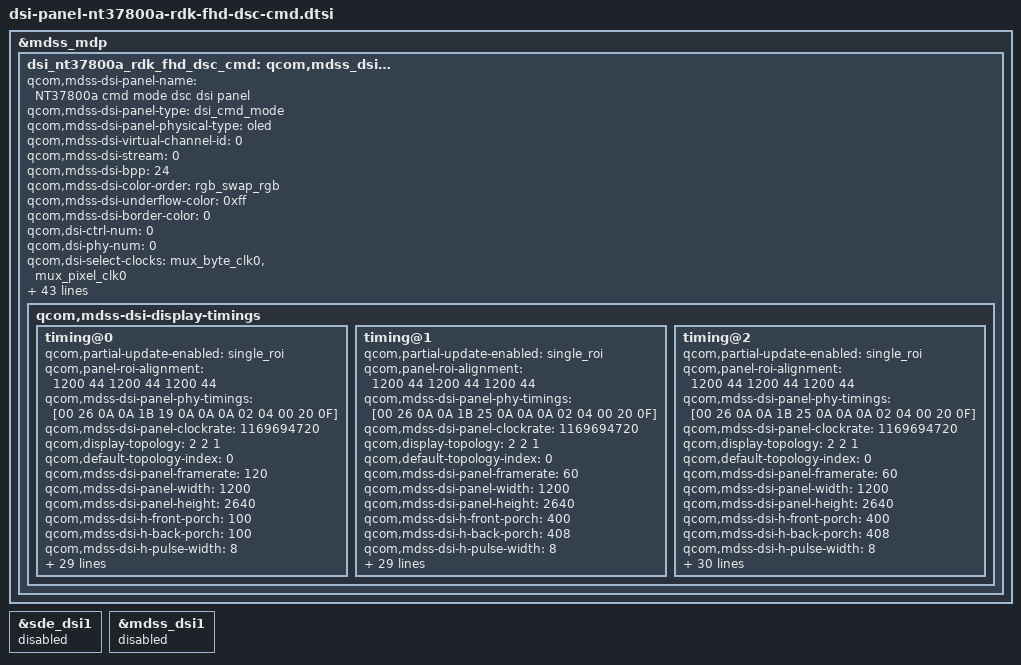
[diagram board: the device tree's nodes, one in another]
/* Copyright (c) 2014, Code Aurora Forum. All rights reserved.
 *
 * This program is free software; you can redistribute it and/or modify
 * it under the terms of the GNU General Public License version 2 and
 * only version 2 as published by the Free Software Foundation.
 *
 * This program is distributed in the hope that it will be useful,
 * but WITHOUT ANY WARRANTY; without even the implied warranty of
 * MERCHANTABILITY or FITNESS FOR A PARTICULAR PURPOSE.  See the
 * GNU General Public License for more details.
 */

&mdss_mdp {
    dsi_nt37800a_rdk_fhd_dsc_cmd: qcom,mdss_dsi_nt37800a_rdk_fhd_dsc_cmd {
        qcom,mdss-dsi-panel-name = "NT37800a cmd mode dsc dsi panel";
		qcom,mdss-dsi-panel-type = "dsi_cmd_mode";
		qcom,mdss-dsi-panel-physical-type = "oled";
		qcom,mdss-dsi-virtual-channel-id = <0>;
		qcom,mdss-dsi-stream = <0>;
		qcom,mdss-dsi-bpp = <24>;
		qcom,mdss-dsi-color-order = "rgb_swap_rgb";
		qcom,mdss-dsi-underflow-color = <0xff>;
		qcom,mdss-dsi-border-color = <0>;
		qcom,dsi-ctrl-num = <0>;
		qcom,dsi-phy-num = <0>;
		qcom,dsi-select-clocks = "mux_byte_clk0", "mux_pixel_clk0";
		qcom,mdss-dsi-traffic-mode = "burst_mode";
		qcom,mdss-dsi-lane-map = "lane_map_0123";
		qcom,mdss-dsi-bllp-eof-power-mode;
		qcom,mdss-dsi-bllp-power-mode;
		qcom,mdss-dsi-lane-0-state;
		qcom,mdss-dsi-lane-1-state;
		qcom,mdss-dsi-lane-2-state;
		qcom,mdss-dsi-lane-3-state;
		qcom,mdss-dsi-reset-sequence = <1 10>, <0 2>, <1 10>;
		lge,mdss-dsi-reset-keep-high-after-off-cmd = <180>;
		qcom,mdss-dsi-dma-trigger = "trigger_sw";
		qcom,mdss-dsi-mdp-trigger = "none";
		qcom,mdss-dsi-te-pin-select = <1>;
		qcom,mdss-dsi-wr-mem-start = <0x2c>;
		qcom,mdss-dsi-wr-mem-continue = <0x3c>;
		qcom,mdss-dsi-te-dcs-command = <1>;
		//qcom,mdss-dsi-te-check-enable;
		//qcom,mdss-dsi-te-using-te-pin;
		qcom,mdss-dsi-lp11-init;
		qcom,mdss-dsi-tx-eot-append;
		qcom,ulps-enabled;
		qcom,suspend-ulps-enabled;

		qcom,mdss-dsi-panel-hdr-enabled;
		qcom,mdss-dsi-panel-hdr-color-primaries = <14880 15935 32435 16555 14945 30910 7790 3415>;
		qcom,mdss-dsi-panel-peak-brightness = <5000000>;		/* max. 500nits */
		qcom,mdss-dsi-panel-blackness-level = <6134>;

		qcom,mdss-pan-physical-width-dimension = <69>;
		qcom,mdss-pan-physical-height-dimension = <158>;

		lge,fps-switch-enabled;
		//lge,use-dim-ctrl;
		/* Brightness Map List */
		lge,blmap = <
			0
			5 5 5 5 5 5 5 5 5 5 6 6 7 7 8 8 9 9 10 10
			11 11 12 12 13 13 14 14 15 15 16 16 17 17 18 18 20 21 23 24
			26 28 29 31 32 34 36 37 39 40 42 44 45 47 48 50 52 53 55 56
			58 61 64 67 70 72 75 78 81 84 87 90 93 95 98 101 104 107 110 113
			116 120 125 130 127 132 136 141 146 151 155 160 165 170 174 179 184 189 193 198
			203 208 212 217 222 227 231 236 241 247 252 258 263 269 274 279 285 290 296 301
			307 312 317 323 328 334 339 344 350 355 361 366 372 377 385 392 400 408 415 423
			430 436 444 451 459 466 474 482 489 497 505 512 520 528 535 543 551 558 568 577
			586 596 605 614 623 632 642 651 660 669 679 688 697 706 715 725 734 743 752 761
			771 780 789 801 812 824 836 847 859 870 882 894 905 917 929 940 952 963 975 987
			998 1010 1022 1033 1045 1056 1068 1079 1090 1102 1113 1124 1135 1146 1158 1169 1180 1191 1202 1214
			1225 1236 1247 1258 1270 1281 1292 1303 1314 1326 1337 1348 1364 1379 1395 1410 1426 1441 1457 1472
			1488 1503 1519 1534 1550 1565 1581 1596 1612 1627 1643 1658 1674 1689 1705 1708 1710 1713 1715 1718
			1720 1723 1725 1728 1730 1733 1735 1738 1740 1743 1745 1748 1750 1753 1755 1758 1762 1765 1768 1772
			1775 1778 1782 1785 1788 1792 1795 1798 1802 1805 1808 1812 1815 1818 1822 1825 1828 1832 1835 1838
			1842 1845 1848 1852 1855 1858 1862 1865 1868 1872 1875 1878 1882 1885 1888 1892 1895 1898 1902 1905
			1908 1912 1915 1918 1922 1925 1928 1932 1935 1938 1942 1945 1948 1952 1955 1958 1962 1965 1968 1972
			1975 1978 1982 1985 1988 1992 1995 1998 2002 2005 2008 2011 2013 2016 2019 2022 2025 2027 2030 2033
			2036 2039 2041 2044 2047
		>;

		lge,blmap-ex = <
			0
			16 16 16 16 16 16 16 16 16 25 35 44 53 62 72 81 90 99 109 118
			127 136 146 155 164 173 183 192 201 210 220 229 238 247 257 266 273 281 288 295
			303 310 317 325 332 339 347 354 361 369 376 383 391 398 405 413 420 427 435 442
			449 457 464 471 479 486 493 501 508 515 523 530 537 545 552 572 592 612 632 652
			672 692 712 732 752 772 792 812 832 852 872 892 912 932 952 972 992 1009 1026 1043
			1060 1076 1093 1110 1127 1144 1161 1178 1195 1212 1228 1245 1262 1279 1296 1310 1325 1339 1353 1368
			1382 1396 1411 1425 1439 1453 1468 1482 1496 1511 1525 1539 1554 1568 1568 1568 1568 1568 1568 1568
			1589 1611 1632 1653 1674 1696 1717 1738 1759 1781 1802 1823 1844 1866 1887 1908 1929 1951 1972 1972
			1972 1972 1972 1972 1972 1972 1972 1972 1972 1972 1972 1972 1972 1972 1972 1972 1972 1972 1972 1972
			1972 1972 1972 1972 1972 1972 1972 1972 1972 1972 1972 1972 1972 1972 1972 1972 1972 1972 1972 1972
			1972 1972 1972 1972 1972 1972 1972 1972 1972 1972 1972 1972 1972 1972 1972 1972 1972 1972 1972 1972
			1972 1972 1972 1972 1972 1972 1972 1972 1972 1972 1972 1972 1972 1972 1972 1972 1972 1972 1972 1972
			1972 1972 1972 1972 1972 1972 1972 1972 1972 1972 1972 1972 1972 1972 1972
		>;

		lge,mdss-dsi-nolp-command = [
			05 01 00 00 00 00 01 38
		];
		lge,mdss-dsi-nolp-command-state = "dsi_lp_mode";
		lge,mdss-dsi-lp2-command = [
			05 01 00 00 00 00 01 39
		];
		lge,mdss-dsi-lp2-command-state = "dsi_lp_mode";

		lge,mdss-dsi-switch-fps-ctrl-command = [
			39 01 00 00 00 00 06 F0 55 AA 52 08 00
			39 01 00 00 00 00 02 2F 00
		];
		lge,mdss-dsi-switch-fps-ctrl-command-state = "dsi_lp_mode";

		qcom,mdss-dsi-display-timings {
			timing@0{
				qcom,partial-update-enabled = "single_roi";
				qcom,panel-roi-alignment = <1200 44 1200 44 1200 44>;
				qcom,mdss-dsi-panel-phy-timings = [00 26 0A 0A 1B 19 0A 0A 0A 02 04 00 20 0F];
				qcom,mdss-dsi-panel-clockrate = <1169694720>;
				qcom,display-topology = <2 2 1>;
				qcom,default-topology-index = <0>;
				qcom,mdss-dsi-panel-framerate = <120>;
				qcom,mdss-dsi-panel-width = <1200>;
				qcom,mdss-dsi-panel-height = <2640>;
				qcom,mdss-dsi-h-front-porch = <100>;
				qcom,mdss-dsi-h-back-porch = <100>;
				qcom,mdss-dsi-h-pulse-width = <8>;
				qcom,mdss-dsi-h-sync-skew = <0>;
				qcom,mdss-dsi-v-back-porch = <14>;
				qcom,mdss-dsi-v-front-porch = <16>;
				qcom,mdss-dsi-v-pulse-width = <2>;
				qcom,mdss-dsi-h-left-border = <0>;
				qcom,mdss-dsi-h-right-border = <0>;
				qcom,mdss-dsi-v-top-border = <0>;
				qcom,mdss-dsi-v-bottom-border = <0>;
				qcom,mdss-dsi-h-sync-pulse = <0>;
				//qcom,mdss-mdp-transfer-time-us = <15000>;

				qcom,mdss-dsi-on-command = [
					/* PMIC Setting */
					39 01 00 00 00 00 06 F0 55 AA 52 08 00
					39 01 00 00 00 00 03 B5 84 42
					39 01 00 00 00 00 02 6F 05
					39 01 00 00 00 00 05 B5 7F 4E 19 51
					39 01 00 00 00 00 02 6F 10
					39 01 00 00 00 00 06 B5 19 19 19 19 19
					39 01 00 00 00 00 02 6F 13
					39 01 00 00 00 00 0D B7 45 56 78 9A BC DE FF FF FF FF FF FF
					39 01 00 00 00 00 02 6F 1F
					39 01 00 00 00 00 19 B7 20 09 F2 DB C4 AD 96 7F 68 51 3A 23 0C FF FF FF FF FF FF FF FF FF FF FF
					39 01 00 00 00 00 07 B7 A9 87 65 43 21 00

					/* 120Hz Driving */
					39 01 00 00 00 00 06 F0 55 AA 52 08 00
					39 01 00 00 00 00 02 6F 2C
					39 01 00 00 00 00 13 B3 0A 3F 0A 3F 07 F3 07 F3 06 12 06 12 03 FB 03 FB 01 B0
					39 01 00 00 00 00 02 6F 3E
					39 01 00 00 00 00 15 B3 01 B0 01 B0 01 B0 01 B0 01 B0 01 B0 01 B0 01 B0 01 B0 01 B0
					39 01 00 00 00 00 13 B4 14 7E 14 7E 0F E6 0F E6 0C 24 0C 24 07 F6 07 F6 03 60
					39 01 00 00 00 00 02 6F 12
					39 01 00 00 00 00 15 B4 03 60 03 60 03 60 03 60 03 60 03 60 03 60 03 60 03 60 03 60
					39 01 00 00 00 00 11 BA 01 8C 00 10 0A 80 80 01 01 8C 00 10 00 10 00 01
					39 01 00 00 00 00 04 C1 00 55 00
					39 01 00 00 00 00 09 C6 33 33 33 33 00 03 00 33
					39 01 00 00 00 00 02 6F 0F
					39 01 00 00 00 00 03 B2 30 20
					39 01 00 00 00 00 06 F0 55 AA 52 08 03
					39 01 00 00 00 00 15 B2 00 40 14 07 01 00 40 14 00 40 14 07 01 07 01 07 01 07 01 00
					39 01 00 00 00 00 08 BB 11 00 1E 52 00 1E 52
					39 01 00 00 00 00 08 BC 11 00 0E 51 00 0E 51
					39 01 00 00 00 00 06 F0 55 AA 52 08 01
					39 01 00 00 00 00 02 C4 00

					/* Initial Code */
					39 01 00 00 00 00 05 FF AA 55 A5 81
					39 01 00 00 00 00 02 6F 0D
					39 01 00 00 00 00 02 F3 CB
					39 01 00 00 00 00 02 6F 44
					39 01 00 00 00 00 03 FB 05 05
					39 01 00 00 00 00 02 6F 48
					39 01 00 00 00 00 03 FB 05 05
					39 01 00 00 00 00 02 6F 0C
					39 01 00 00 00 00 02 F3 3F
					39 01 00 00 00 00 05 FF AA 55 A5 00
					39 01 00 00 00 00 02 35 00
					39 01 00 00 00 00 06 F0 55 AA 52 08 00
					39 01 00 00 00 00 02 C0 76

					39 01 00 00 00 00 05 3B 00 10 00 10
					39 01 00 00 00 00 02 53 20
					39 01 00 00 00 00 05 2A 00 00 04 AF
					39 01 00 00 00 00 05 2B 00 00 0A 4F
					39 01 00 00 00 00 02 90 01
					39 01 00 00 00 00 13 91 89 28 00 2C C2 00 02 2C 04 7C 00 08 02 3C 02 15 10 F0
					39 01 00 00 00 00 02 03 01
					39 01 00 00 00 00 02 2C 00
					39 01 00 00 00 00 06 F0 55 AA 52 08 00
					39 01 00 00 00 00 02 2F 02
					05 01 00 00 82 00 01 11
					05 01 00 00 00 00 01 29
				];

				qcom,mdss-dsi-post-panel-on-command = [
					//05 01 00 00 78 00 01 12
					//39 01 00 00 00 00 03 51 07 FF
				];

				qcom,mdss-dsi-off-command = [
					05 01 00 00 78 00 01 28
					05 01 00 00 96 00 01 10
				];

				qcom,compression-mode = "dsc";
				qcom,mdss-dsc-version = <0x11>;
				qcom,mdss-dsc-scr-version = <0x1>;
				qcom,mdss-dsc-slice-height = <44>;
				qcom,mdss-dsc-slice-width = <600>;
				qcom,mdss-dsc-slice-per-pkt = <2>;
				qcom,mdss-dsc-bit-per-component = <8>;
				qcom,mdss-dsc-bit-per-pixel = <8>;
				qcom,lm-split = <600 600>;
				qcom,mdss-dsc-encoders = <2>;
				qcom,mdss-dsc-block-prediction-enable;

				qcom,mdss-dsi-on-command-state = "dsi_lp_mode";
				qcom,mdss-dsi-off-command-state = "dsi_lp_mode";

				qcom,mode-control-dsi-state = "dsi_lp_mode";
				qcom,mdss-dsi-pps-command-state = "dsi_hs_mode";
			};

			timing@1{
				qcom,partial-update-enabled = "single_roi";
				qcom,panel-roi-alignment = <1200 44 1200 44 1200 44>;
				qcom,mdss-dsi-panel-phy-timings = [00 26 0A 0A 1B 25 0A 0A 0A 02 04 00 20 0F];
				qcom,mdss-dsi-panel-clockrate = <1169694720>;
				qcom,display-topology = <2 2 1>;
				qcom,default-topology-index = <0>;
				qcom,mdss-dsi-panel-framerate = <60>;
				qcom,mdss-dsi-panel-width = <1200>;
				qcom,mdss-dsi-panel-height = <2640>;
				qcom,mdss-dsi-h-front-porch = <400>;
				qcom,mdss-dsi-h-back-porch = <408>;
				qcom,mdss-dsi-h-pulse-width = <8>;
				qcom,mdss-dsi-h-sync-skew = <0>;
				qcom,mdss-dsi-v-back-porch = <14>;
				qcom,mdss-dsi-v-front-porch = <16>;
				qcom,mdss-dsi-v-pulse-width = <2>;
				qcom,mdss-dsi-h-left-border = <0>;
				qcom,mdss-dsi-h-right-border = <0>;
				qcom,mdss-dsi-v-top-border = <0>;
				qcom,mdss-dsi-v-bottom-border = <0>;
				qcom,mdss-dsi-h-sync-pulse = <0>;
				//qcom,mdss-mdp-transfer-time-us = <15000>;

				qcom,mdss-dsi-on-command = [
					/* PMIC Setting */
					39 01 00 00 00 00 06 F0 55 AA 52 08 00
					39 01 00 00 00 00 03 B5 84 42
					39 01 00 00 00 00 02 6F 05
					39 01 00 00 00 00 05 B5 7F 4E 19 51
					39 01 00 00 00 00 02 6F 10
					39 01 00 00 00 00 06 B5 19 19 19 19 19
					39 01 00 00 00 00 02 6F 13
					39 01 00 00 00 00 0D B7 45 56 78 9A BC DE FF FF FF FF FF FF
					39 01 00 00 00 00 02 6F 1F
					39 01 00 00 00 00 19 B7 20 09 F2 DB C4 AD 96 7F 68 51 3A 23 0C FF FF FF FF FF FF FF FF FF FF FF
					39 01 00 00 00 00 07 B7 A9 87 65 43 21 00

					/* 120Hz Driving */
					39 01 00 00 00 00 06 F0 55 AA 52 08 00
					39 01 00 00 00 00 02 6F 2C
					39 01 00 00 00 00 13 B3 0A 3F 0A 3F 07 F3 07 F3 06 12 06 12 03 FB 03 FB 01 B0
					39 01 00 00 00 00 02 6F 3E
					39 01 00 00 00 00 15 B3 01 B0 01 B0 01 B0 01 B0 01 B0 01 B0 01 B0 01 B0 01 B0 01 B0
					39 01 00 00 00 00 13 B4 14 7E 14 7E 0F E6 0F E6 0C 24 0C 24 07 F6 07 F6 03 60
					39 01 00 00 00 00 02 6F 12
					39 01 00 00 00 00 15 B4 03 60 03 60 03 60 03 60 03 60 03 60 03 60 03 60 03 60 03 60
					39 01 00 00 00 00 11 BA 01 8C 00 10 0A 80 80 01 01 8C 00 10 00 10 00 01
					39 01 00 00 00 00 04 C1 00 55 00
					39 01 00 00 00 00 09 C6 33 33 33 33 00 03 00 33
					39 01 00 00 00 00 02 6F 0F
					39 01 00 00 00 00 03 B2 30 20
					39 01 00 00 00 00 06 F0 55 AA 52 08 03
					39 01 00 00 00 00 15 B2 00 40 14 07 01 00 40 14 00 40 14 07 01 07 01 07 01 07 01 00
					39 01 00 00 00 00 08 BB 11 00 1E 52 00 1E 52
					39 01 00 00 00 00 08 BC 11 00 0E 51 00 0E 51
					39 01 00 00 00 00 06 F0 55 AA 52 08 01
					39 01 00 00 00 00 02 C4 00

					/* Initial Code */
					39 01 00 00 00 00 05 FF AA 55 A5 81
					39 01 00 00 00 00 02 6F 0D
					39 01 00 00 00 00 02 F3 CB
					39 01 00 00 00 00 02 6F 44
					39 01 00 00 00 00 03 FB 05 05
					39 01 00 00 00 00 02 6F 48
					39 01 00 00 00 00 03 FB 05 05
					39 01 00 00 00 00 02 6F 0C
					39 01 00 00 00 00 02 F3 3F
					39 01 00 00 00 00 05 FF AA 55 A5 00
					39 01 00 00 00 00 02 35 00
					39 01 00 00 00 00 06 F0 55 AA 52 08 00
					39 01 00 00 00 00 02 C0 76

					39 01 00 00 00 00 05 3B 00 10 00 10
					39 01 00 00 00 00 02 53 20
					39 01 00 00 00 00 05 2A 00 00 04 AF
					39 01 00 00 00 00 05 2B 00 00 0A 4F
					39 01 00 00 00 00 02 90 01
					39 01 00 00 00 00 13 91 89 28 00 2C C2 00 02 2C 04 7C 00 08 02 3C 02 15 10 F0
					39 01 00 00 00 00 02 03 01
					39 01 00 00 00 00 02 2C 00
					39 01 00 00 00 00 06 F0 55 AA 52 08 00
					39 01 00 00 00 00 02 2F 01
					05 01 00 00 82 00 01 11
					05 01 00 00 00 00 01 29
				];

				qcom,mdss-dsi-post-panel-on-command = [
					//05 01 00 00 78 00 01 12
					//39 01 00 00 00 00 03 51 07 FF
				];

				qcom,mdss-dsi-off-command = [
					05 01 00 00 78 00 01 28
					05 01 00 00 96 00 01 10
				];

				qcom,compression-mode = "dsc";
				qcom,mdss-dsc-version = <0x11>;
				qcom,mdss-dsc-scr-version = <0x1>;
				qcom,mdss-dsc-slice-height = <44>;
				qcom,mdss-dsc-slice-width = <600>;
				qcom,mdss-dsc-slice-per-pkt = <2>;
				qcom,mdss-dsc-bit-per-component = <8>;
				qcom,mdss-dsc-bit-per-pixel = <8>;
				qcom,lm-split = <600 600>;
				qcom,mdss-dsc-encoders = <2>;
				qcom,mdss-dsc-block-prediction-enable;

				qcom,mdss-dsi-on-command-state = "dsi_lp_mode";
				qcom,mdss-dsi-off-command-state = "dsi_lp_mode";

				qcom,mode-control-dsi-state = "dsi_lp_mode";
				qcom,mdss-dsi-pps-command-state = "dsi_hs_mode";
			};

			timing@2{
				qcom,partial-update-enabled = "single_roi";
				qcom,panel-roi-alignment = <1200 44 1200 44 1200 44>;
				qcom,mdss-dsi-panel-phy-timings = [00 26 0A 0A 1B 25 0A 0A 0A 02 04 00 20 0F];
				qcom,mdss-dsi-panel-clockrate = <1169694720>;
				qcom,display-topology = <2 2 1>;
				qcom,default-topology-index = <0>;
				qcom,mdss-dsi-panel-framerate = <60>;
				qcom,mdss-dsi-panel-width = <1200>;
				qcom,mdss-dsi-panel-height = <2640>;
				qcom,mdss-dsi-h-front-porch = <400>;
				qcom,mdss-dsi-h-back-porch = <408>;
				qcom,mdss-dsi-h-pulse-width = <8>;
				qcom,mdss-dsi-h-sync-skew = <0>;
				qcom,mdss-dsi-v-back-porch = <14>;
				qcom,mdss-dsi-v-front-porch = <16>;
				qcom,mdss-dsi-v-pulse-width = <2>;
				qcom,mdss-dsi-h-left-border = <0>;
				qcom,mdss-dsi-h-right-border = <0>;
				qcom,mdss-dsi-v-top-border = <0>;
				qcom,mdss-dsi-v-bottom-border = <0>;
				qcom,mdss-dsi-h-sync-pulse = <0>;
				//qcom,mdss-mdp-transfer-time-us = <15000>;
				lge,mdss-dsi-panel-framerate-div = <2>;

				qcom,mdss-dsi-on-command = [
					/* PMIC Setting */
					39 01 00 00 00 00 06 F0 55 AA 52 08 00
					39 01 00 00 00 00 03 B5 84 42
					39 01 00 00 00 00 02 6F 05
					39 01 00 00 00 00 05 B5 7F 4E 19 51
					39 01 00 00 00 00 02 6F 10
					39 01 00 00 00 00 06 B5 19 19 19 19 19
					39 01 00 00 00 00 02 6F 13
					39 01 00 00 00 00 0D B7 45 56 78 9A BC DE FF FF FF FF FF FF
					39 01 00 00 00 00 02 6F 1F
					39 01 00 00 00 00 19 B7 20 09 F2 DB C4 AD 96 7F 68 51 3A 23 0C FF FF FF FF FF FF FF FF FF FF FF
					39 01 00 00 00 00 07 B7 A9 87 65 43 21 00

					/* 120Hz Driving */
					39 01 00 00 00 00 06 F0 55 AA 52 08 00
					39 01 00 00 00 00 02 6F 2C
					39 01 00 00 00 00 13 B3 0A 3F 0A 3F 07 F3 07 F3 06 12 06 12 03 FB 03 FB 01 B0
					39 01 00 00 00 00 02 6F 3E
					39 01 00 00 00 00 15 B3 01 B0 01 B0 01 B0 01 B0 01 B0 01 B0 01 B0 01 B0 01 B0 01 B0
					39 01 00 00 00 00 13 B4 14 7E 14 7E 0F E6 0F E6 0C 24 0C 24 07 F6 07 F6 03 60
					39 01 00 00 00 00 02 6F 12
					39 01 00 00 00 00 15 B4 03 60 03 60 03 60 03 60 03 60 03 60 03 60 03 60 03 60 03 60
					39 01 00 00 00 00 11 BA 01 8C 00 10 0A 80 80 01 01 8C 00 10 00 10 00 01
					39 01 00 00 00 00 04 C1 00 55 00
					39 01 00 00 00 00 09 C6 33 33 33 33 00 03 00 33
					39 01 00 00 00 00 02 6F 0F
					39 01 00 00 00 00 03 B2 30 20
					39 01 00 00 00 00 06 F0 55 AA 52 08 03
					39 01 00 00 00 00 15 B2 00 40 14 07 01 00 40 14 00 40 14 07 01 07 01 07 01 07 01 00
					39 01 00 00 00 00 08 BB 11 00 1E 52 00 1E 52
					39 01 00 00 00 00 08 BC 11 00 0E 51 00 0E 51
					39 01 00 00 00 00 06 F0 55 AA 52 08 01
					39 01 00 00 00 00 02 C4 00

					/* Initial Code */
					39 01 00 00 00 00 05 FF AA 55 A5 81
					39 01 00 00 00 00 02 6F 0D
					39 01 00 00 00 00 02 F3 CB
					39 01 00 00 00 00 02 6F 44
					39 01 00 00 00 00 03 FB 05 05
					39 01 00 00 00 00 02 6F 48
					39 01 00 00 00 00 03 FB 05 05
					39 01 00 00 00 00 02 6F 0C
					39 01 00 00 00 00 02 F3 3F
					39 01 00 00 00 00 05 FF AA 55 A5 00
					39 01 00 00 00 00 02 35 00
					39 01 00 00 00 00 06 F0 55 AA 52 08 00
					39 01 00 00 00 00 02 C0 76

					39 01 00 00 00 00 05 3B 00 10 00 10
					39 01 00 00 00 00 02 53 20
					39 01 00 00 00 00 05 2A 00 00 04 AF
					39 01 00 00 00 00 05 2B 00 00 0A 4F
					39 01 00 00 00 00 02 90 01
					39 01 00 00 00 00 13 91 89 28 00 2C C2 00 02 2C 04 7C 00 08 02 3C 02 15 10 F0
					39 01 00 00 00 00 02 03 01
					39 01 00 00 00 00 02 2C 00
					39 01 00 00 00 00 06 F0 55 AA 52 08 00
					39 01 00 00 00 00 02 2F 01
					05 01 00 00 82 00 01 11
					05 01 00 00 00 00 01 29
				];

				qcom,mdss-dsi-post-panel-on-command = [
					//05 01 00 00 78 00 01 12
					//39 01 00 00 00 00 03 51 07 FF
				];

				qcom,mdss-dsi-off-command = [
					05 01 00 00 78 00 01 28
					05 01 00 00 96 00 01 10
				];

				qcom,compression-mode = "dsc";
				qcom,mdss-dsc-version = <0x11>;
				qcom,mdss-dsc-scr-version = <0x1>;
				qcom,mdss-dsc-slice-height = <44>;
				qcom,mdss-dsc-slice-width = <600>;
				qcom,mdss-dsc-slice-per-pkt = <2>;
				qcom,mdss-dsc-bit-per-component = <8>;
				qcom,mdss-dsc-bit-per-pixel = <8>;
				qcom,lm-split = <600 600>;
				qcom,mdss-dsc-encoders = <2>;
				qcom,mdss-dsc-block-prediction-enable;

				qcom,mdss-dsi-on-command-state = "dsi_lp_mode";
				qcom,mdss-dsi-off-command-state = "dsi_lp_mode";

				qcom,mode-control-dsi-state = "dsi_lp_mode";
				qcom,mdss-dsi-pps-command-state = "dsi_hs_mode";
			};
		};
	};
};

&sde_dsi1 {
	status = "disabled";
};

&mdss_dsi1 {
	status = "disabled";
};
